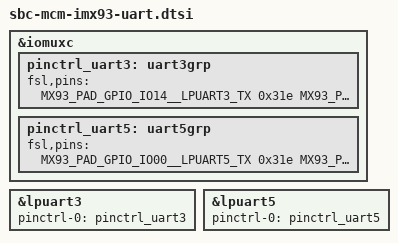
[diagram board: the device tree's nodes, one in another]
// SPDX-License-Identifier: (GPL-2.0+ OR MIT)
/*
 * Copyright 2024 Compulab
 */

&iomuxc {
	pinctrl_uart3: uart3grp {
		fsl,pins = <
			MX93_PAD_GPIO_IO14__LPUART3_TX	0x31e
			MX93_PAD_GPIO_IO15__LPUART3_RX	0x31e
		>;
	};
	pinctrl_uart5: uart5grp {
		fsl,pins = <
			MX93_PAD_GPIO_IO00__LPUART5_TX		0x31e
			MX93_PAD_GPIO_IO01__LPUART5_RX		0x31e
			MX93_PAD_GPIO_IO02__LPUART5_CTS_B	0x31e
			MX93_PAD_GPIO_IO03__LPUART5_RTS_B	0x31e
		>;
	};
};
&lpuart3 {
	pinctrl-names = "default";
	pinctrl-0 = <&pinctrl_uart3>;
	/*fsl,uart-has-rtscts;*/
	status = "okay";
};

&lpuart5 {
	pinctrl-names = "default";
	pinctrl-0 = <&pinctrl_uart5>;
	/*fsl,uart-has-rtscts;*/
	status = "okay";
};

